# S6E1A1xB register map
Vendor: Cypress; File version: 2.1
CPU: CM0PLUS r0p1, little endian, no MPU, no FPU, 2 interrupt priority bits
Registers are 32-bit, read-write, reset 0x0 unless marked. A register's access mark holds for its fields unless they carry their own. Offsets are from the block's base; [hi:lo] are bit positions; {n}, {i} and the like mark numbered series; 'fields as' and 'values as' point back to an identical list.

## MFT_PPG — PPG Configuration Registers
Base 0x40024000
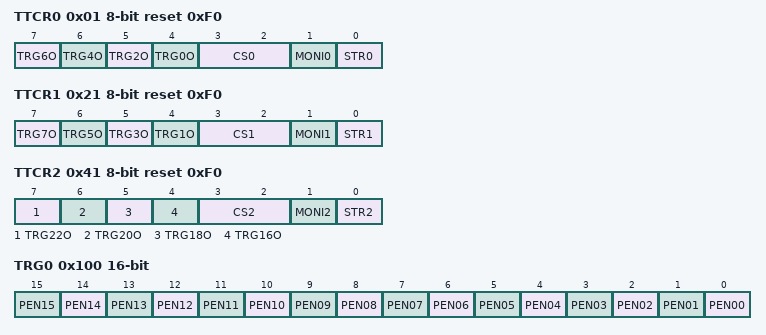
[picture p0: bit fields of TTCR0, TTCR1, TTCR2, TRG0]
0x01 TTCR0 8-bit reset 0xF0 — PPG Start Trigger Control Register 0 [BHW]
  [7] TRG6O wo — PPG6 trigger stop bit
  [6] TRG4O wo — PPG4 trigger stop bit
  [5] TRG2O wo — PPG2 trigger stop bit
  [4] TRG0O wo — PPG0 trigger stop bit
  [3:2] CS0 — 8-bit UP counter clock select bits for comparison
  [1] MONI0 ro — 8-bit UP counter operation state monitor bit for comparison
  [0] STR0 wo — 8-bit UP counter operation enable bit for comparison
0x09 COMP0 8-bit — PPG Compare Register 0 [BHW]
0x0C COMP2 8-bit — PPG Compare Register 2 [BHW]
0x11 COMP4 8-bit — PPG Compare Register 4 [BHW]
0x14 COMP6 8-bit — PPG Compare Register 6 [BHW]
0x21 TTCR1 8-bit reset 0xF0 — PPG Start Trigger Control Register 1 [BHW]
  [7] TRG7O wo — PPG7 trigger stop bit
  [6] TRG5O wo — PPG5 trigger stop bit
  [5] TRG3O wo — PPG3 trigger stop bit
  [4] TRG1O wo — PPG1 trigger stop bit
  [3:2] CS1 — 8-bit UP counter clock select bits for comparison
  [1] MONI1 ro — 8-bit UP counter operation state monitor bit for comparison
  [0] STR1 wo — 8-bit UP counter operation enable bit for comparison
0x29 COMP1 8-bit — PPG Compare Register 1 [BHW]
0x2C COMP3 8-bit — PPG Compare Register 3 [BHW]
0x31 COMP5 8-bit — PPG Compare Register 5 [BHW]
0x34 COMP7 8-bit — PPG Compare Register 7 [BHW]
0x41 TTCR2 8-bit reset 0xF0 — PPG Start Trigger Control Register 2 [BHW]
  [7] TRG22O wo — PPG22 trigger stop bit
  [6] TRG20O wo — PPG20 trigger stop bit
  [5] TRG18O wo — PPG18 trigger stop bit
  [4] TRG16O wo — PPG16 trigger stop bit
  [3:2] CS2 — 8-bit UP counter clock select bits for comparison
  [1] MONI2 ro — 8-bit UP counter operation state monitor bit for comparison
  [0] STR2 wo — 8-bit UP counter operation enable bit for comparison
0x49 COMP8 8-bit — PPG Compare Register 8 [BHW]
0x4C COMP10 8-bit — PPG Compare Register 10 [BHW]
0x51 COMP12 8-bit — PPG Compare Register 12 [BHW]
0x54 COMP14 8-bit — PPG Compare Register 14 [BHW]
0x100 TRG0 16-bit — PPG Start Register 0 [BHW]
  [n] PEN{n:02} (n=0..15) — PPG{n} Start Trigger bit
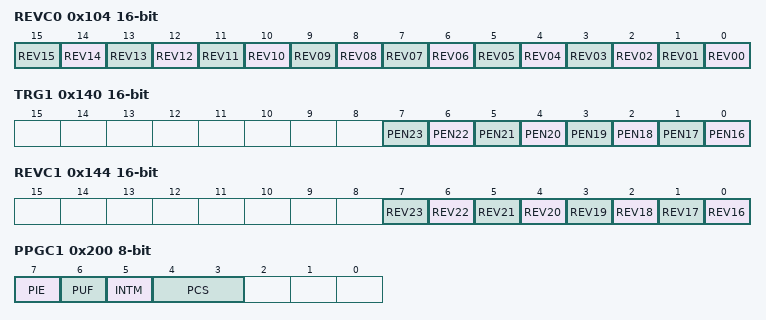
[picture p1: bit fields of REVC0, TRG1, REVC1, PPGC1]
0x104 REVC0 16-bit — Output Reverse Register 0 [BHW]
  [n] REV{n:02} (n=0..15) — PPG{n} Output Reverse Enable bit
0x140 TRG1 16-bit — PPG Start Register 1 [BHW]
  [n-16] PEN{n} (n=16..23) — PPG{n} Start Trigger bit
0x144 REVC1 16-bit — Output Reverse Register 1 [BHW]
  [n-16] REV{n} (n=16..23) — PPG{n} Output Reverse Enable bit
0x200 PPGC1 8-bit — PPG Operation Mode Control Register 1 [BHW]
  [7] PIE — PPG Interrupt Enable bit
  [6] PUF — PPG Counter Underflow bit
  [5] INTM — Interrupt Mode Select bit
  [4:3] PCS — PPG DOWN Counter Operation Clock Select bits
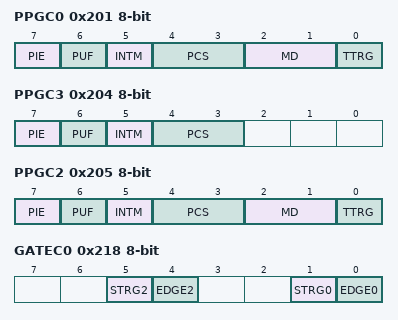
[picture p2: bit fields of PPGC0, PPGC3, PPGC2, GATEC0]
0x201 PPGC0 8-bit — PPG Operation Mode Control Register 0 [BHW]
  [7] PIE — PPG Interrupt Enable bit
  [6] PUF — PPG Counter Underflow bit
  [5] INTM — Interrupt Mode Select bit
  [4:3] PCS — PPG DOWN Counter Operation Clock Select bits
  [2:1] MD — PPG Operation Mode Set bits
  [0] TTRG — PPG start trigger select bit
0x204 PPGC3 8-bit — PPG Operation Mode Control Register 3 [BHW]
  fields as PPGC1
0x205 PPGC2 8-bit — PPG Operation Mode Control Register 2 [BHW]
  fields as PPGC0
{0x208+4i} PRLL{i} 8-bit (i=0..3) — PPG{i} Reload Registers Low [BHW]
  [7:0] PRLL — Reload Registers Low
{0x209+4i} PRLH{i} 8-bit (i=0..3) — PPG{i} Reload Registers High [BHW]
  [7:0] PRLH — Reload Registers High
0x218 GATEC0 8-bit — PPG Gate Function Control Register 0 [BHW]
  [5] STRG2 — Select trigger bit for PPG2
  [4] EDGE2 — Start Effective Level Select bit for PPG2
  [1] STRG0 — Select trigger bit for PPG0
  [0] EDGE0 — Start Effective Level Select bit for PPG0
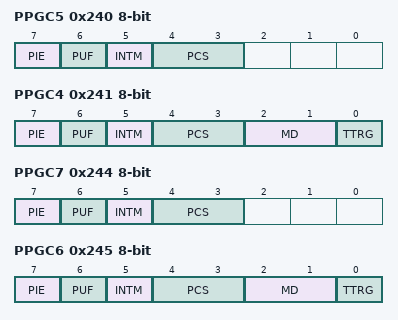
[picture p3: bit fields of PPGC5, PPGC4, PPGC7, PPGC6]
0x240 PPGC5 8-bit — PPG Operation Mode Control Register 5 [BHW]
  fields as PPGC1
0x241 PPGC4 8-bit — PPG Operation Mode Control Register 4 [BHW]
  fields as PPGC0
0x244 PPGC7 8-bit — PPG Operation Mode Control Register 7 [BHW]
  fields as PPGC1
0x245 PPGC6 8-bit — PPG Operation Mode Control Register 6 [BHW]
  fields as PPGC0
{0x238+4i} PRLL{i} 8-bit (i=4..7) — PPG{i} Reload Registers Low [BHW]
  [7:0] PRLL — Reload Registers Low
{0x239+4i} PRLH{i} 8-bit (i=4..7) — PPG{i} Reload Registers High [BHW]
  [7:0] PRLH — Reload Registers High
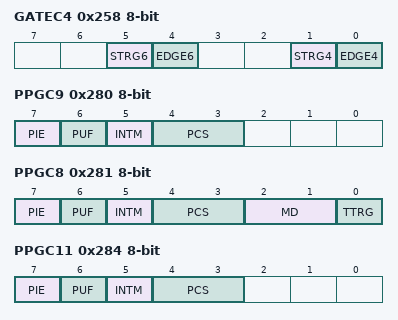
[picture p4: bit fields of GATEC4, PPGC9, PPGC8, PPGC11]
0x258 GATEC4 8-bit — PPG Gate Function Control Register 4 [BHW]
  [5] STRG6 — Select trigger bit for PPG6
  [4] EDGE6 — Start Effective Level Select bit for PPG6
  [1] STRG4 — Select trigger bit for PPG4
  [0] EDGE4 — Start Effective Level Select bit for PPG4
0x280 PPGC9 8-bit — PPG Operation Mode Control Register 9 [BHW]
  fields as PPGC1
0x281 PPGC8 8-bit — PPG Operation Mode Control Register 8 [BHW]
  fields as PPGC0
0x284 PPGC11 8-bit — PPG Operation Mode Control Register 11 [BHW]
  fields as PPGC1
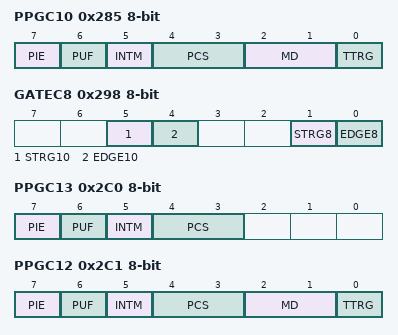
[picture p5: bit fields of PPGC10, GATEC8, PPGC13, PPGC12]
0x285 PPGC10 8-bit — PPG Operation Mode Control Register 10 [BHW]
  fields as PPGC0
{0x268+4i} PRLL{i} 8-bit (i=8..11) — PPG{i} Reload Registers Low [BHW]
  [7:0] PRLL — Reload Registers Low
{0x269+4i} PRLH{i} 8-bit (i=8..11) — PPG{i} Reload Registers High [BHW]
  [7:0] PRLH — Reload Registers High
0x298 GATEC8 8-bit — PPG Gate Function Control Register 8 [BHW]
  [5] STRG10 — Select trigger bit for PPG10
  [4] EDGE10 — Start Effective Level Select bit for PPG10
  [1] STRG8 — Select trigger bit for PPG8
  [0] EDGE8 — Start Effective Level Select bit for PPG8
0x2C0 PPGC13 8-bit — PPG Operation Mode Control Register 13 [BHW]
  fields as PPGC1
0x2C1 PPGC12 8-bit — PPG Operation Mode Control Register 12 [BHW]
  fields as PPGC0
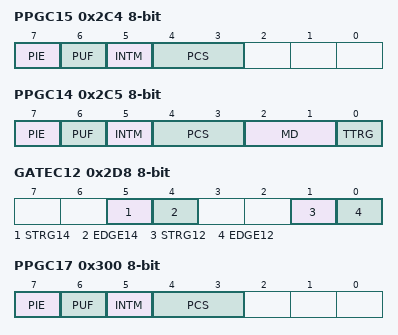
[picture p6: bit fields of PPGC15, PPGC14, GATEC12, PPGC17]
0x2C4 PPGC15 8-bit — PPG Operation Mode Control Register 15 [BHW]
  fields as PPGC1
0x2C5 PPGC14 8-bit — PPG Operation Mode Control Register 14 [BHW]
  fields as PPGC0
{0x298+4i} PRLL{i} 8-bit (i=12..15) — PPG{i} Reload Registers Low [BHW]
  [7:0] PRLL — Reload Registers Low
{0x299+4i} PRLH{i} 8-bit (i=12..15) — PPG{i} Reload Registers High [BHW]
  [7:0] PRLH — Reload Registers High
0x2D8 GATEC12 8-bit — PPG Gate Function Control Register 12 [BHW]
  [5] STRG14 — Select trigger bit for PPG14
  [4] EDGE14 — Start Effective Level Select bit for PPG14
  [1] STRG12 — Select trigger bit for PPG12
  [0] EDGE12 — Start Effective Level Select bit for PPG12
0x300 PPGC17 8-bit — PPG Operation Mode Control Register 17 [BHW]
  fields as PPGC1
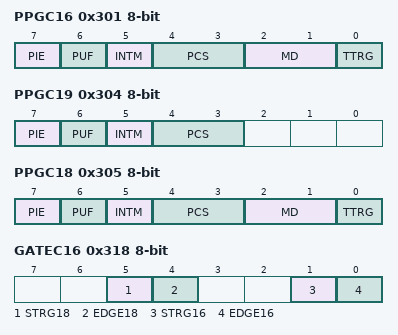
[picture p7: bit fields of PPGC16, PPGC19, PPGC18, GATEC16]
0x301 PPGC16 8-bit — PPG Operation Mode Control Register 16 [BHW]
  fields as PPGC0
0x304 PPGC19 8-bit — PPG Operation Mode Control Register 19 [BHW]
  fields as PPGC1
0x305 PPGC18 8-bit — PPG Operation Mode Control Register 18 [BHW]
  fields as PPGC0
{0x2C8+4i} PRLL{i} 8-bit (i=16..19) — PPG{i} Reload Registers Low [BHW]
  [7:0] PRLL — Reload Registers Low
{0x2C9+4i} PRLH{i} 8-bit (i=16..19) — PPG{i} Reload Registers High [BHW]
  [7:0] PRLH — Reload Registers High
0x318 GATEC16 8-bit — PPG Gate Function Control Register 16 [BHW]
  [5] STRG18 — Select trigger bit for PPG18
  [4] EDGE18 — Start Effective Level Select bit for PPG18
  [1] STRG16 — Select trigger bit for PPG16
  [0] EDGE16 — Start Effective Level Select bit for PPG16
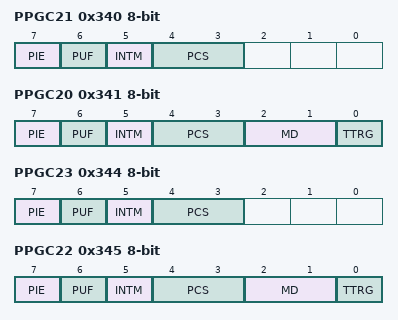
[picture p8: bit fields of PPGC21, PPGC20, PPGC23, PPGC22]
0x340 PPGC21 8-bit — PPG Operation Mode Control Register 21 [BHW]
  fields as PPGC1
0x341 PPGC20 8-bit — PPG Operation Mode Control Register 20 [BHW]
  fields as PPGC0
0x344 PPGC23 8-bit — PPG Operation Mode Control Register 23 [BHW]
  fields as PPGC1
0x345 PPGC22 8-bit — PPG Operation Mode Control Register 22 [BHW]
  fields as PPGC0
{0x2F8+4i} PRLL{i} 8-bit (i=20..23) — PPG{i} Reload Registers Low [BHW]
  [7:0] PRLL — Reload Registers Low
{0x2F9+4i} PRLH{i} 8-bit (i=20..23) — PPG{i} Reload Registers High [BHW]
  [7:0] PRLH — Reload Registers High
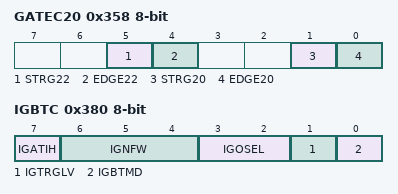
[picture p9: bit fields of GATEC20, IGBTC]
0x358 GATEC20 8-bit — PPG Gate Function Control Register 20 [BHW]
  [5] STRG22 — Select trigger bit for PPG22
  [4] EDGE22 — Start Effective Level Select bit for PPG22
  [1] STRG20 — Select trigger bit for PPG20
  [0] EDGE20 — Start Effective Level Select bit for PPG20
0x380 IGBTC 8-bit — IGBT Mode Control Register [BHW]
  [7] IGATIH — Stop prohibition mode selection in output active bit
  [6:4] IGNFW — Noise filter width selection bit
  [3:2] IGOSEL — Output level selection bit
  [1] IGTRGLV — Trigger input level selection bit
  [0] IGBTMD — IGBT mode selection bit

## Notices in the file
Copyright (C) 2013-2016, Cypress Semiconductor Corporation or a
subsidiary of Cypress Semiconductor Corporation.  All rights reserved.
This software, including source code, documentation and related
materials ("Software"), is owned by Cypress Semiconductor Corporation or
one of its subsidiaries ("Cypress") and is protected by and subject to
worldwide patent protection (United States and foreign), United States
copyright laws and international treaty provisions. Therefore, you may use
this Software only as provided in the license agreement accompanying the
software package from which you obtained this Software ("EULA").
If no EULA applies, Cypress hereby grants you a personal, non-exclusive,
non-transferable license to copy, modify, and compile the
Software source code solely for use in connection with Cypress's
integrated circuit products.  Any reproduction, modification, translation,
compilation, or representation of this Software except as specified
above is prohibited without the express written permission of Cypress.
Disclaimer: THIS SOFTWARE IS PROVIDED AS-IS, WITH NO
WARRANTY OF ANY KIND, EXPRESS OR IMPLIED, INCLUDING,
BUT NOT LIMITED TO, NONINFRINGEMENT, IMPLIED
WARRANTIES OF MERCHANTABILITY AND FITNESS FOR A
PARTICULAR PURPOSE. Cypress reserves the right to make
changes to the Software without notice. Cypress does not assume any
liability arising out of the application or use of the Software or any
product or circuit described in the Software. Cypress does not
authorize its products for use in any products where a malfunction or
failure of the Cypress product may reasonably be expected to result in
significant property damage, injury or death ("High Risk Product"). By
including Cypress's product in a High Risk Product, the manufacturer
of such system or application assumes all risk of such use and in doing
so agrees to indemnify Cypress against all liability.
